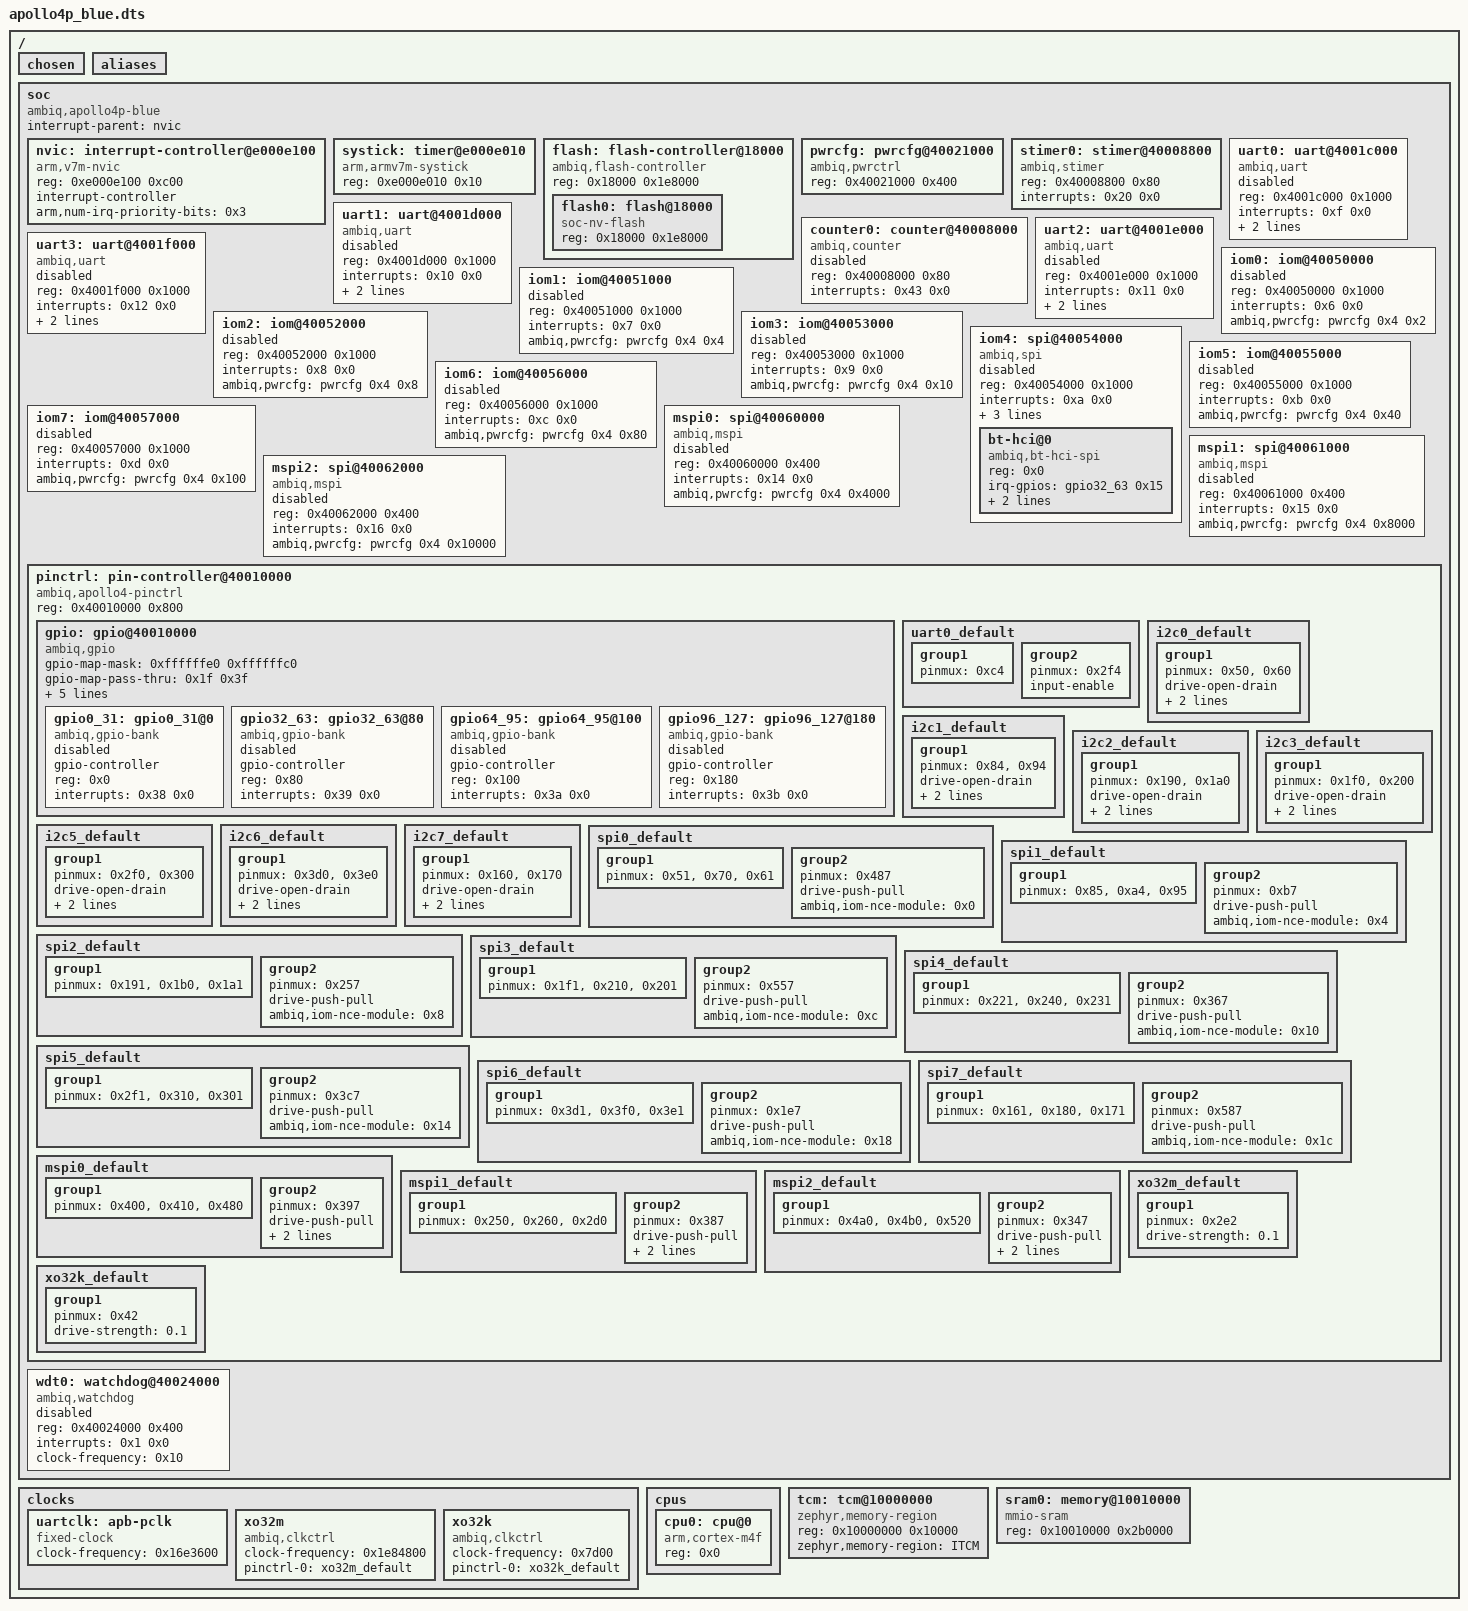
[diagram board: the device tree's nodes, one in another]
/dts-v1/;

/ {
	#address-cells = < 0x1 >;
	#size-cells = < 0x1 >;
	chosen {
	};
	aliases {
	};
	soc {
		#address-cells = < 0x1 >;
		#size-cells = < 0x1 >;
		compatible = "ambiq,apollo4p-blue", "ambiq,apollo4x", "simple-bus";
		interrupt-parent = < &nvic >;
		ranges;
		nvic: interrupt-controller@e000e100 {
			#address-cells = < 0x1 >;
			compatible = "arm,v7m-nvic";
			reg = < 0xe000e100 0xc00 >;
			interrupt-controller;
			#interrupt-cells = < 0x2 >;
			arm,num-irq-priority-bits = < 0x3 >;
			phandle = < 0x1 >;
		};
		systick: timer@e000e010 {
			compatible = "arm,armv7m-systick";
			reg = < 0xe000e010 0x10 >;
		};
		flash: flash-controller@18000 {
			compatible = "ambiq,flash-controller";
			reg = < 0x18000 0x1e8000 >;
			#address-cells = < 0x1 >;
			#size-cells = < 0x1 >;
			flash0: flash@18000 {
				compatible = "soc-nv-flash";
				reg = < 0x18000 0x1e8000 >;
			};
		};
		pwrcfg: pwrcfg@40021000 {
			compatible = "ambiq,pwrctrl";
			reg = < 0x40021000 0x400 >;
			#pwrcfg-cells = < 0x2 >;
			phandle = < 0x3 >;
		};
		stimer0: stimer@40008800 {
			compatible = "ambiq,stimer";
			reg = < 0x40008800 0x80 >;
			interrupts = < 0x20 0x0 >;
			status = "okay";
		};
		counter0: counter@40008000 {
			compatible = "ambiq,counter";
			reg = < 0x40008000 0x80 >;
			interrupts = < 0x43 0x0 >;
			status = "disabled";
		};
		uart0: uart@4001c000 {
			compatible = "ambiq,uart", "arm,pl011";
			reg = < 0x4001c000 0x1000 >;
			interrupts = < 0xf 0x0 >;
			interrupt-names = "UART0";
			status = "disabled";
			clocks = < &uartclk >;
			ambiq,pwrcfg = < &pwrcfg 0x4 0x200 >;
		};
		uart1: uart@4001d000 {
			compatible = "ambiq,uart", "arm,pl011";
			reg = < 0x4001d000 0x1000 >;
			interrupts = < 0x10 0x0 >;
			interrupt-names = "UART1";
			status = "disabled";
			clocks = < &uartclk >;
			ambiq,pwrcfg = < &pwrcfg 0x4 0x400 >;
		};
		uart2: uart@4001e000 {
			compatible = "ambiq,uart", "arm,pl011";
			reg = < 0x4001e000 0x1000 >;
			interrupts = < 0x11 0x0 >;
			interrupt-names = "UART2";
			status = "disabled";
			clocks = < &uartclk >;
			ambiq,pwrcfg = < &pwrcfg 0x4 0x800 >;
		};
		uart3: uart@4001f000 {
			compatible = "ambiq,uart", "arm,pl011";
			reg = < 0x4001f000 0x1000 >;
			interrupts = < 0x12 0x0 >;
			interrupt-names = "UART3";
			status = "disabled";
			clocks = < &uartclk >;
			ambiq,pwrcfg = < &pwrcfg 0x4 0x1000 >;
		};
		iom0: iom@40050000 {
			reg = < 0x40050000 0x1000 >;
			#address-cells = < 0x1 >;
			#size-cells = < 0x0 >;
			interrupts = < 0x6 0x0 >;
			status = "disabled";
			ambiq,pwrcfg = < &pwrcfg 0x4 0x2 >;
		};
		iom1: iom@40051000 {
			reg = < 0x40051000 0x1000 >;
			#address-cells = < 0x1 >;
			#size-cells = < 0x0 >;
			interrupts = < 0x7 0x0 >;
			status = "disabled";
			ambiq,pwrcfg = < &pwrcfg 0x4 0x4 >;
		};
		iom2: iom@40052000 {
			reg = < 0x40052000 0x1000 >;
			#address-cells = < 0x1 >;
			#size-cells = < 0x0 >;
			interrupts = < 0x8 0x0 >;
			status = "disabled";
			ambiq,pwrcfg = < &pwrcfg 0x4 0x8 >;
		};
		iom3: iom@40053000 {
			reg = < 0x40053000 0x1000 >;
			#address-cells = < 0x1 >;
			#size-cells = < 0x0 >;
			interrupts = < 0x9 0x0 >;
			status = "disabled";
			ambiq,pwrcfg = < &pwrcfg 0x4 0x10 >;
		};
		iom4: spi@40054000 {
			compatible = "ambiq,spi";
			reg = < 0x40054000 0x1000 >;
			#address-cells = < 0x1 >;
			#size-cells = < 0x0 >;
			interrupts = < 0xa 0x0 >;
			cs-gpios = < &gpio32_63 0x16 0x11 >;
			clock-frequency = < 0x16e3600 >;
			status = "disabled";
			ambiq,pwrcfg = < &pwrcfg 0x4 0x20 >;
			bt-hci@0 {
				compatible = "ambiq,bt-hci-spi";
				reg = < 0x0 >;
				irq-gpios = < &gpio32_63 0x15 0x0 >;
				reset-gpios = < &gpio32_63 0x17 0x1 >;
				clkreq-gpios = < &gpio32_63 0x14 0x0 >;
			};
		};
		iom5: iom@40055000 {
			reg = < 0x40055000 0x1000 >;
			#address-cells = < 0x1 >;
			#size-cells = < 0x0 >;
			interrupts = < 0xb 0x0 >;
			status = "disabled";
			ambiq,pwrcfg = < &pwrcfg 0x4 0x40 >;
		};
		iom6: iom@40056000 {
			reg = < 0x40056000 0x1000 >;
			#address-cells = < 0x1 >;
			#size-cells = < 0x0 >;
			interrupts = < 0xc 0x0 >;
			status = "disabled";
			ambiq,pwrcfg = < &pwrcfg 0x4 0x80 >;
		};
		iom7: iom@40057000 {
			reg = < 0x40057000 0x1000 >;
			#address-cells = < 0x1 >;
			#size-cells = < 0x0 >;
			interrupts = < 0xd 0x0 >;
			status = "disabled";
			ambiq,pwrcfg = < &pwrcfg 0x4 0x100 >;
		};
		mspi0: spi@40060000 {
			compatible = "ambiq,mspi";
			reg = < 0x40060000 0x400 >;
			interrupts = < 0x14 0x0 >;
			#address-cells = < 0x1 >;
			#size-cells = < 0x0 >;
			status = "disabled";
			ambiq,pwrcfg = < &pwrcfg 0x4 0x4000 >;
		};
		mspi1: spi@40061000 {
			compatible = "ambiq,mspi";
			reg = < 0x40061000 0x400 >;
			interrupts = < 0x15 0x0 >;
			#address-cells = < 0x1 >;
			#size-cells = < 0x0 >;
			status = "disabled";
			ambiq,pwrcfg = < &pwrcfg 0x4 0x8000 >;
		};
		mspi2: spi@40062000 {
			compatible = "ambiq,mspi";
			reg = < 0x40062000 0x400 >;
			interrupts = < 0x16 0x0 >;
			#address-cells = < 0x1 >;
			#size-cells = < 0x0 >;
			status = "disabled";
			ambiq,pwrcfg = < &pwrcfg 0x4 0x10000 >;
		};
		pinctrl: pin-controller@40010000 {
			compatible = "ambiq,apollo4-pinctrl";
			reg = < 0x40010000 0x800 >;
			#address-cells = < 0x1 >;
			#size-cells = < 0x0 >;
			gpio: gpio@40010000 {
				compatible = "ambiq,gpio";
				gpio-map-mask = < 0xffffffe0 0xffffffc0 >;
				gpio-map-pass-thru = < 0x1f 0x3f >;
				gpio-map = < 0x0 0x0 &gpio0_31 0x0 0x0 0x20 0x0 &gpio32_63 0x0 0x0 0x40 0x0 &gpio64_95 0x0 0x0 0x60 0x0 &gpio96_127 0x0 0x0 >;
				reg = < 0x40010000 >;
				#gpio-cells = < 0x2 >;
				#address-cells = < 0x1 >;
				#size-cells = < 0x0 >;
				ranges;
				gpio0_31: gpio0_31@0 {
					compatible = "ambiq,gpio-bank";
					gpio-controller;
					#gpio-cells = < 0x2 >;
					reg = < 0x0 >;
					interrupts = < 0x38 0x0 >;
					status = "disabled";
					phandle = < 0x5 >;
				};
				gpio32_63: gpio32_63@80 {
					compatible = "ambiq,gpio-bank";
					gpio-controller;
					#gpio-cells = < 0x2 >;
					reg = < 0x80 >;
					interrupts = < 0x39 0x0 >;
					status = "disabled";
					phandle = < 0x4 >;
				};
				gpio64_95: gpio64_95@100 {
					compatible = "ambiq,gpio-bank";
					gpio-controller;
					#gpio-cells = < 0x2 >;
					reg = < 0x100 >;
					interrupts = < 0x3a 0x0 >;
					status = "disabled";
					phandle = < 0x6 >;
				};
				gpio96_127: gpio96_127@180 {
					compatible = "ambiq,gpio-bank";
					gpio-controller;
					#gpio-cells = < 0x2 >;
					reg = < 0x180 >;
					interrupts = < 0x3b 0x0 >;
					status = "disabled";
					phandle = < 0x7 >;
				};
			};
			uart0_default: uart0_default {
				group1 {
					pinmux = < 0xc4 >;
				};
				group2 {
					pinmux = < 0x2f4 >;
					input-enable;
				};
			};
			i2c0_default: i2c0_default {
				group1 {
					pinmux = < 0x50 >, < 0x60 >;
					drive-open-drain;
					drive-strength = "0.5";
					bias-pull-up;
				};
			};
			i2c1_default: i2c1_default {
				group1 {
					pinmux = < 0x84 >, < 0x94 >;
					drive-open-drain;
					drive-strength = "0.5";
					bias-pull-up;
				};
			};
			i2c2_default: i2c2_default {
				group1 {
					pinmux = < 0x190 >, < 0x1a0 >;
					drive-open-drain;
					drive-strength = "0.5";
					bias-pull-up;
				};
			};
			i2c3_default: i2c3_default {
				group1 {
					pinmux = < 0x1f0 >, < 0x200 >;
					drive-open-drain;
					drive-strength = "0.5";
					bias-pull-up;
				};
			};
			i2c5_default: i2c5_default {
				group1 {
					pinmux = < 0x2f0 >, < 0x300 >;
					drive-open-drain;
					drive-strength = "0.5";
					bias-pull-up;
				};
			};
			i2c6_default: i2c6_default {
				group1 {
					pinmux = < 0x3d0 >, < 0x3e0 >;
					drive-open-drain;
					drive-strength = "0.5";
					bias-pull-up;
				};
			};
			i2c7_default: i2c7_default {
				group1 {
					pinmux = < 0x160 >, < 0x170 >;
					drive-open-drain;
					drive-strength = "0.5";
					bias-pull-up;
				};
			};
			spi0_default: spi0_default {
				group1 {
					pinmux = < 0x51 >, < 0x70 >, < 0x61 >;
				};
				group2 {
					pinmux = < 0x487 >;
					drive-push-pull;
					ambiq,iom-nce-module = < 0x0 >;
				};
			};
			spi1_default: spi1_default {
				group1 {
					pinmux = < 0x85 >, < 0xa4 >, < 0x95 >;
				};
				group2 {
					pinmux = < 0xb7 >;
					drive-push-pull;
					ambiq,iom-nce-module = < 0x4 >;
				};
			};
			spi2_default: spi2_default {
				group1 {
					pinmux = < 0x191 >, < 0x1b0 >, < 0x1a1 >;
				};
				group2 {
					pinmux = < 0x257 >;
					drive-push-pull;
					ambiq,iom-nce-module = < 0x8 >;
				};
			};
			spi3_default: spi3_default {
				group1 {
					pinmux = < 0x1f1 >, < 0x210 >, < 0x201 >;
				};
				group2 {
					pinmux = < 0x557 >;
					drive-push-pull;
					ambiq,iom-nce-module = < 0xc >;
				};
			};
			spi4_default: spi4_default {
				group1 {
					pinmux = < 0x221 >, < 0x240 >, < 0x231 >;
				};
				group2 {
					pinmux = < 0x367 >;
					drive-push-pull;
					ambiq,iom-nce-module = < 0x10 >;
				};
			};
			spi5_default: spi5_default {
				group1 {
					pinmux = < 0x2f1 >, < 0x310 >, < 0x301 >;
				};
				group2 {
					pinmux = < 0x3c7 >;
					drive-push-pull;
					ambiq,iom-nce-module = < 0x14 >;
				};
			};
			spi6_default: spi6_default {
				group1 {
					pinmux = < 0x3d1 >, < 0x3f0 >, < 0x3e1 >;
				};
				group2 {
					pinmux = < 0x1e7 >;
					drive-push-pull;
					ambiq,iom-nce-module = < 0x18 >;
				};
			};
			spi7_default: spi7_default {
				group1 {
					pinmux = < 0x161 >, < 0x180 >, < 0x171 >;
				};
				group2 {
					pinmux = < 0x587 >;
					drive-push-pull;
					ambiq,iom-nce-module = < 0x1c >;
				};
			};
			mspi0_default: mspi0_default {
				group1 {
					pinmux = < 0x400 >, < 0x410 >, < 0x480 >;
				};
				group2 {
					pinmux = < 0x397 >;
					drive-push-pull;
					drive-strength = "0.5";
					ambiq,iom-nce-module = < 0x20 >;
				};
			};
			mspi1_default: mspi1_default {
				group1 {
					pinmux = < 0x250 >, < 0x260 >, < 0x2d0 >;
				};
				group2 {
					pinmux = < 0x387 >;
					drive-push-pull;
					drive-strength = "0.5";
					ambiq,iom-nce-module = < 0x22 >;
				};
			};
			mspi2_default: mspi2_default {
				group1 {
					pinmux = < 0x4a0 >, < 0x4b0 >, < 0x520 >;
				};
				group2 {
					pinmux = < 0x347 >;
					drive-push-pull;
					drive-strength = "0.5";
					ambiq,iom-nce-module = < 0x24 >;
				};
			};
			xo32m_default: xo32m_default {
				phandle = < 0x8 >;
				group1 {
					pinmux = < 0x2e2 >;
					drive-strength = "0.1";
				};
			};
			xo32k_default: xo32k_default {
				phandle = < 0x9 >;
				group1 {
					pinmux = < 0x42 >;
					drive-strength = "0.1";
				};
			};
		};
		wdt0: watchdog@40024000 {
			compatible = "ambiq,watchdog";
			reg = < 0x40024000 0x400 >;
			interrupts = < 0x1 0x0 >;
			clock-frequency = < 0x10 >;
			status = "disabled";
		};
	};
	clocks {
		uartclk: apb-pclk {
			compatible = "fixed-clock";
			clock-frequency = < 0x16e3600 >;
			#clock-cells = < 0x0 >;
			phandle = < 0x2 >;
		};
		xo32m: xo32m {
			compatible = "ambiq,clkctrl";
			clock-frequency = < 0x1e84800 >;
			#clock-cells = < 0x1 >;
			pinctrl-0 = < &xo32m_default >;
			pinctrl-names = "default";
		};
		xo32k: xo32k {
			compatible = "ambiq,clkctrl";
			clock-frequency = < 0x7d00 >;
			#clock-cells = < 0x1 >;
			pinctrl-0 = < &xo32k_default >;
			pinctrl-names = "default";
		};
	};
	cpus {
		#address-cells = < 0x1 >;
		#size-cells = < 0x0 >;
		cpu0: cpu@0 {
			compatible = "arm,cortex-m4f";
			reg = < 0x0 >;
		};
	};
	tcm: tcm@10000000 {
		compatible = "zephyr,memory-region";
		reg = < 0x10000000 0x10000 >;
		zephyr,memory-region = "ITCM";
	};
	sram0: memory@10010000 {
		compatible = "mmio-sram";
		reg = < 0x10010000 0x2b0000 >;
	};
};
